# STM32H563 register map
File version: 0.4
CPU: CM33 r0p0, little endian, MPU, FPU, 4 interrupt priority bits
Registers are 32-bit, read-write, reset 0x0 unless marked. A register's access mark holds for its fields unless they carry their own. Offsets are from the block's base; [hi:lo] are bit positions.

## TIM13 — General-purpose timers
Base 0x40001C00
Same registers: TIM14 0x40002000, SEC_TIM13 0x50001C00, SEC_TIM14 0x50002000
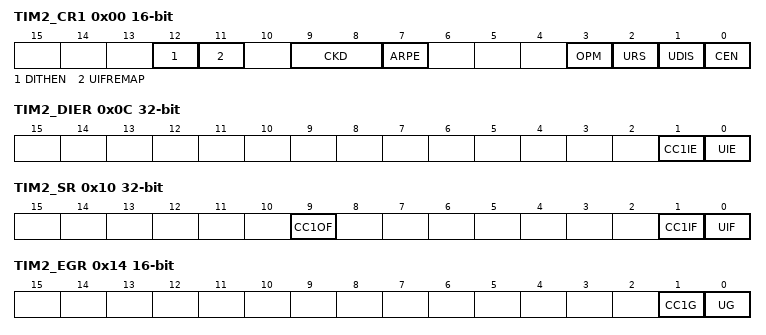
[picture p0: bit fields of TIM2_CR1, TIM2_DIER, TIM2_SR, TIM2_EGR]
0x00 TIM2_CR1 16-bit — TIM2 control register 1
  [12] DITHEN — Dithering Enable Note: The DITHEN bit can only be modified when CEN bit is reset.
  [11] UIFREMAP — UIF status bit remapping
  [9:8] CKD — Clock division This bit-field indicates the division ratio between the timer clock (tim_ker_ck) frequency and sampling clock used by the digital filters (tim_etr_in, tim_tix),
  [7] ARPE — Auto-reload preload enable
  [3] OPM — One-pulse mode
  [2] URS — Update request source This bit is set and cleared by software to select the UEV event sources. Counter overflow/underflow Setting the UG bit Update generation through the slave mode controller
  [1] UDIS — Update disable This bit is set and cleared by software to enable/disable UEV event generation. Counter overflow/underflow Setting the UG bit Update generation through the slave mode controller Buffered registers are then loaded with their preload values.
  [0] CEN — Counter enable Note: External clock, gated mode and encoder mode can work only if the CEN bit has been previously set by software. However trigger mode can set the CEN bit automatically by hardware. CEN is cleared automatically in one-pulse mode, when an update event occurs.
0x0C TIM2_DIER — TIM2 DMA/Interrupt enable register
  [1] CC1IE — Capture/Compare 1 interrupt enable
  [0] UIE — Update interrupt enable
0x10 TIM2_SR — TIM2 status register
  [9] CC1OF — Capture/Compare 1 overcapture flag This flag is set by hardware only when the corresponding channel is configured in input capture mode. It is cleared by software by writing it to ‘0’.
  [1] CC1IF — Capture/compare 1 interrupt flag This flag is set by hardware. It is cleared by software (input capture or output compare mode) or by reading the TIMx_CCR1 register (input capture mode only). If channel CC1 is configured as output: this flag is set when the content of the counter TIMx_CNT matches the content of the TIMx_CCR1 register. When the content of TIMx_CCR1 is greater than the content of TIMx_ARR, the CC1IF bit goes high on the counter overflow (in up-counting and up/down-counting modes) or underflow (in downcounting mode). There are 3 possible options for flag setting in center-aligned mode, refer to the CMS bits in the TIMx_CR1 register for the full description. If channel CC1 is configured as input: this bit is set when counter value has been captured in TIMx_CCR1 register (an edge has been detected on IC1, as per the edge sensitivity defined with the CC1P and CC1NP bits setting, in TIMx_CCER).
  [0] UIF — Update interrupt flag This bit is set by hardware on an update event. It is cleared by software. At overflow or underflow and if UDIS=0 in the TIMx_CR1 register. When CNT is reinitialized by software using the UG bit in TIMx_EGR register, if URS=0 and UDIS=0 in the TIMx_CR1 register. When CNT is reinitialized by a trigger event (refer to the synchro control register description), if URS=0 and UDIS=0 in the TIMx_CR1 register.
0x14 TIM2_EGR 16-bit wo — TIM2 event generation register
  [1] CC1G — Capture/compare 1 generation This bit is set by software in order to generate an event, it is automatically cleared by hardware. If channel CC1 is configured as output: CC1IF flag is set, Corresponding interrupt or DMA request is sent if enabled. If channel CC1 is configured as input: The current value of the counter is captured in TIMx_CCR1 register. The CC1IF flag is set, the corresponding interrupt or DMA request is sent if enabled. The CC1OF flag is set if the CC1IF flag was already high.
  [0] UG — Update generation This bit can be set by software, it is automatically cleared by hardware.
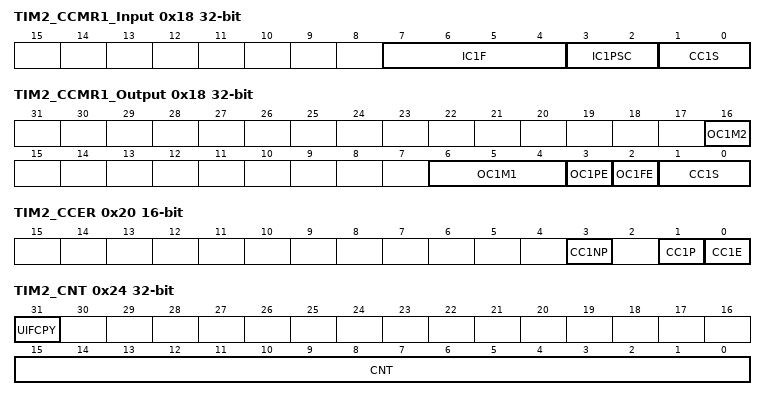
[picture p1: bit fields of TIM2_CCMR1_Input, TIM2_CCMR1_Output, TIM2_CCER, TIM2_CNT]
0x18 TIM2_CCMR1_Input — TIM2 capture/compare mode register 1 [alternate]
  [7:4] IC1F — Input capture 1 filter This bit-field defines the frequency used to sample tim_ti1 input and the length of the digital filter applied to tim_ti1. The digital filter is made of an event counter in which N consecutive events are needed to validate a transition on the output:
  [3:2] IC1PSC — Input capture 1 prescaler This bit-field defines the ratio of the prescaler acting on CC1 input (tim_ic1). The prescaler is reset as soon as CC1E=0 (TIMx_CCER register).
  [1:0] CC1S — Capture/Compare 1 selection This bit-field defines the direction of the channel (input/output) as well as the used input. Note: CC1S bits are writable only when the channel is OFF (CC1E = 0 in TIMx_CCER).
0x18 TIM2_CCMR1_Output (alternate view of TIM2_CCMR1_Input) — TIM2 capture/compare mode register 1 [alternate]
  [16] OC1M2 — Output compare 1 mode These bits define the behavior of the output reference signal tim_oc1ref from which tim_oc1 is derived. tim_oc1ref is active high whereas tim_oc1 active level depends on CC1P bit. Note: In PWM mode, the tim_ocref_clr level changes only when the result of the comparison changes or when the output compare mode switches from “frozen” mode to “PWM” mode.
  [6:4] OC1M1 — Output compare 1 mode These bits define the behavior of the output reference signal tim_oc1ref from which tim_oc1 is derived. tim_oc1ref is active high whereas tim_oc1 active level depends on CC1P bit. Note: In PWM mode, the tim_ocref_clr level changes only when the result of the comparison changes or when the output compare mode switches from “frozen” mode to “PWM” mode.
  [3] OC1PE — Output compare 1 preload enable Note: The PWM mode can be used without validating the preload register only in one-pulse mode (OPM bit set in TIMx_CR1 register). Else the behavior is not guaranteed.
  [2] OC1FE — Output compare 1 fast enable This bit decreases the latency between a trigger event and a transition on the timer output. It must be used in one-pulse mode (OPM bit set in TIMx_CR1 register), to have the output pulse starting as soon as possible after the starting trigger.
  [1:0] CC1S — Capture/Compare 1 selection This bit-field defines the direction of the channel (input/output) as well as the used input. Note: CC1S bits are writable only when the channel is OFF (CC1E = 0 in TIMx_CCER).
0x20 TIM2_CCER 16-bit — TIM2 capture/compare enable register
  [3] CC1NP — Capture/Compare 1 output Polarity. CC1 channel configured as output: CC1NP must be kept cleared in this case. CC1 channel configured as input: This bit is used in conjunction with CC1P to define tim_ti1fp1/tim_ti2fp1 polarity. refer to CC1P description.
  [1] CC1P — Capture/Compare 1 output Polarity. When CC1 channel is configured as input, both CC1NP/CC1P bits select the active polarity of TI1FP1 and TI2FP1 for trigger or capture operations. CC1NP=0, CC1P=0: non-inverted/rising edge. The circuit is sensitive to TIxFP1 rising edge (capture or trigger operations in reset, external clock or trigger mode), TIxFP1 is not inverted (trigger operation in gated mode or encoder mode). CC1NP=0, CC1P=1: inverted/falling edge. The circuit is sensitive to TIxFP1 falling edge (capture or trigger operations in reset, external clock or trigger mode), TIxFP1 is inverted (trigger operation in gated mode or encoder mode). CC1NP=1, CC1P=1: non-inverted/both edges. The circuit is sensitive to both TIxFP1 rising and falling edges (capture or trigger operations in reset, external clock or trigger mode), TIxFP1is not inverted (trigger operation in gated mode). This configuration must not be used in encoder mode. CC1NP=1, CC1P=0: this configuration is reserved, it must not be used.
  [0] CC1E — Capture/Compare 1 output enable.
0x24 TIM2_CNT — TIM2 counter
  [31] UIFCPY — UIF Copy
  [15:0] CNT — or UIFCPY: Value depends on IUFREMAP in TIMx_CR1. If UIFREMAP = 0 nullMost significant bit of counter value If UIFREMAP = 1 UIFCPY: UIF Copy This bit is a read-only copy of the UIF bit of the TIMx_ISR register nullLeast significant part of counter value Non-dithering mode (DITHEN = 0) The register holds the counter value. Dithering mode (DITHEN = 1) The register holds the non-dithered part in CNT[30:0]. The fractional part is not available.
0x28 TIM2_PSC 16-bit — TIM2 prescaler
  [15:0] PSC — Prescaler value The counter clock frequency tim_cnt_ck is equal to ftim_psc_ck / (PSC[15:0] + 1). PSC contains the value to be loaded in the active prescaler register at each update event (including when the counter is cleared through UG bit of TIMx_EGR register or through trigger controller when configured in “reset mode”).
0x2C TIM2_ARR reset 0xFFFFFFFF — TIM2 auto-reload register
  [19:0] ARR — Auto-reload value ARR is the value to be loaded in the actual auto-reload register. Refer to the for more details about ARR update and behavior. The counter is blocked while the auto-reload value is null. Non-dithering mode (DITHEN = 0) The register holds the auto-reload value. Dithering mode (DITHEN = 1) The register holds the integer part in ARR[31:4]. The ARR[3:0] bitfield contains the dithered part.
0x34 TIM2_CCR1 — TIM2 capture/compare register 1
  [19:0] CCR1 — Capture/compare 1 value If channel CC1 is configured as output: CCR1 is the value to be loaded in the actual capture/compare 1 register (preload value). It is loaded permanently if the preload feature is not selected in the TIMx_CCMR1 register (bit OC1PE). Else the preload value is copied in the active capture/compare 1 register when an update event occurs. The active capture/compare register contains the value to be compared to the counter TIMx_CNT and signaled on tim_oc1 output. Non-dithering mode (DITHEN = 0) The register holds the compare value. Dithering mode (DITHEN = 1) The register holds the integer part in CCR1[31:4]. The CCR1[3:0] bitfield contains the dithered part. If channel CC1 is configured as input: CCR1 is the counter value transferred by the last input capture 1 event (tim_ic1). The TIMx_CCR1 register is read-only and cannot be programmed. Non-dithering mode (DITHEN = 0) The register holds the capture value. Dithering mode (DITHEN = 1) The register holds the capture in CCR1[31:0]. The CCR1[3:0] bits are reset.
0x5C TIM2_TISEL — TIM2 timer input selection register
  [3:0] TI1SEL — Selects tim_ti1[0..15] input ... Refer to for product specific implementation.
